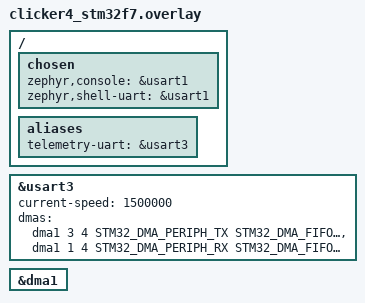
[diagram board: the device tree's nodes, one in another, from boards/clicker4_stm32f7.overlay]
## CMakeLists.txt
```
cmake_minimum_required(VERSION 3.20.0)

list(APPEND BOARD_ROOT ${CMAKE_CURRENT_SOURCE_DIR}/../..)

find_package(Zephyr REQUIRED HINTS $ENV{ZEPHYR_BASE})
project(zbus_uart_telemetry C)

target_include_directories(app PRIVATE include)

target_sources(app PRIVATE
  src/main.c
  src/channels.c
  src/host_command_dispatch.c
  src/sensor_stubs.c
  src/telemetry_encode.c
  src/uart_shared.c
  src/uart_publisher.c
  src/uart_subscriber.c
)

# Export HEX to a stable project-local path for external flash tools (e.g. CodeGrip).
set(CODEGRIP_OUTPUT_DIR "${CMAKE_CURRENT_SOURCE_DIR}/output")
set(CODEGRIP_INPUT_HEX "${PROJECT_BINARY_DIR}/zephyr/zephyr.hex")
set(CODEGRIP_OUTPUT_HEX "${CODEGRIP_OUTPUT_DIR}/zephyr-clicker4_stm32f7.hex")

add_custom_command(
  OUTPUT "${CODEGRIP_OUTPUT_HEX}"
  COMMAND ${CMAKE_COMMAND} -E make_directory "${CODEGRIP_OUTPUT_DIR}"
  COMMAND ${CMAKE_COMMAND} -E copy_if_different "${CODEGRIP_INPUT_HEX}" "${CODEGRIP_OUTPUT_HEX}"
  DEPENDS "${CODEGRIP_INPUT_HEX}"
  COMMENT "Exporting zephyr.hex for CodeGrip"
  VERBATIM
)

add_custom_target(export_codegrip_hex ALL
  DEPENDS "${CODEGRIP_OUTPUT_HEX}"
)
```

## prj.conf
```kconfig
CONFIG_SERIAL=y
CONFIG_ARM_MPU=y
CONFIG_NOCACHE_MEMORY=y
CONFIG_UART_ASYNC_API=y
CONFIG_UART_INTERRUPT_DRIVEN=y
CONFIG_UART_LINE_CTRL=y

CONFIG_ZBUS=y

CONFIG_THREAD_NAME=y
CONFIG_MAIN_STACK_SIZE=2048

CONFIG_LOG=y
CONFIG_LOG_MODE_DEFERRED=y
CONFIG_LOG_DEFAULT_LEVEL=3
CONFIG_LOG_BACKEND_UART=y
CONFIG_CONSOLE=y
CONFIG_UART_CONSOLE=y

CONFIG_ASSERT=y
```

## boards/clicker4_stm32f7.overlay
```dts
#include <zephyr/dt-bindings/dma/stm32_dma.h>

/ {
    chosen {
        zephyr,console = &usart1;
        zephyr,shell-uart = &usart1;
    };

    aliases {
        telemetry-uart = &usart3;
    };
};

&usart3 {
    current-speed = <1500000>;
    dmas = <&dma1 3 4 STM32_DMA_PERIPH_TX STM32_DMA_FIFO_1_4>,
           <&dma1 1 4 STM32_DMA_PERIPH_RX STM32_DMA_FIFO_1_4>;
    dma-names = "tx", "rx";
};

&dma1 {
    status = "okay";
};
```

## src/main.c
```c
#include <zephyr/kernel.h>
#include <zephyr/logging/log.h>

#include "app_threads.h"

LOG_MODULE_REGISTER(app_main, LOG_LEVEL_ERR);

int main(void)
{
    int ret = uart_shared_start();
    if (ret != 0) {
        LOG_ERR("UART shared transport failed to start (%d); stubs not started", ret);
        while (1) {
            k_sleep(K_SECONDS(1));
        }
    }

    ret = uart_publisher_start();
    if (ret != 0) {
        LOG_ERR("UART publisher failed to start (%d); stubs not started", ret);
        while (1) {
            k_sleep(K_SECONDS(1));
        }
    }

    ret = uart_subscriber_start();
    if (ret != 0) {
        LOG_ERR("UART subscriber failed to start (%d); stubs not started", ret);
        while (1) {
            k_sleep(K_SECONDS(1));
        }
    }

    lsm6dsox_stub_start();
    ads1115_stub_start();
    ina3221_stub_start();
    bq76942_stub_start();
    ina226_stub_start();
    heartbeat_stub_start();
    rc_command_stub_start();
    host_command_stub_start();

    while (1) {
        k_sleep(K_SECONDS(1));
    }

    return 0;
}
```

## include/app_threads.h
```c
#ifndef PROJECT_APP_THREADS_H_
#define PROJECT_APP_THREADS_H_

void lsm6dsox_stub_start(void);
void ads1115_stub_start(void);
void ina3221_stub_start(void);
void bq76942_stub_start(void);
void ina226_stub_start(void);
void heartbeat_stub_start(void);
void rc_command_stub_start(void);
void host_command_stub_start(void);
int uart_shared_start(void);
int uart_publisher_start(void);
int uart_subscriber_start(void);

#endif
```

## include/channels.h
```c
#ifndef PROJECT_CHANNELS_H_
#define PROJECT_CHANNELS_H_

/*
 * Compatibility umbrella header.
 * Prefer including telemetry_channels.h or host_channels.h directly.
 */

#include "host_channels.h"
#include "telemetry_channels.h"

#endif
```

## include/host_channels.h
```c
#ifndef PROJECT_HOST_CHANNELS_H_
#define PROJECT_HOST_CHANNELS_H_

#include <zephyr/zbus/zbus.h>

#include "messages.h"

/*
 * Host-to-MCU command channels (not forwarded over telemetry UART).
 * New host command message types should add a dedicated channel here.
 */
ZBUS_CHAN_DECLARE(servo_control_chan);
ZBUS_CHAN_DECLARE(host_heartbeat_chan);

#endif
```

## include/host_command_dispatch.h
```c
#ifndef PROJECT_HOST_COMMAND_DISPATCH_H_
#define PROJECT_HOST_COMMAND_DISPATCH_H_

#include <stdbool.h>

/*
 * Dispatch one host command line (without trailing newline).
 * Returns true if a known command was parsed and published.
 */
bool host_command_dispatch_line(const char *line);

#endif
```

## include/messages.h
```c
#ifndef PROJECT_MESSAGES_H_
#define PROJECT_MESSAGES_H_

#include <stdbool.h>
#include <stdint.h>

/*
 * Message schema definitions (payload only).
 *
 * Extension flow:
 * 1) Add/modify a struct here (keep `t_ms` + `seq` for telemetry messages).
 * 2) Bind topic->message in topic_registry.h.
 * 3) Add channel default in src/channels.c.
 * 4) Add encoder in telemetry_encode.c.
 * 5) Publish data from a producer thread/stub.
 */

struct heartbeat_msg {
    uint32_t t_ms;
    uint32_t seq;
};

struct rc_command_msg {
    uint32_t t_ms;
    uint32_t seq;
    int8_t steering;
    int8_t throttle;
    bool high_gear;
    bool diff_lock;
    bool override_mode;
    bool connected;
};

struct servo_control_msg {
    uint32_t t_ms;
    uint32_t seq;
    int8_t steering;
    int8_t throttle;
    bool high_gear;
    bool front_diff;
    bool rear_diff;
    int8_t extra1;
    int8_t extra2;
};

struct host_heartbeat_msg {
    uint32_t t_ms;
    uint32_t seq;
};

struct lsm6dsox_msg {
    uint32_t t_ms;
    uint32_t seq;
    float ax_mg;
    float ay_mg;
    float az_mg;
    float gx_mdps;
    float gy_mdps;
    float gz_mdps;
    float temp_cdeg;
};

struct ads1115_msg {
    uint32_t t_ms;
    uint32_t seq;
    float ain0_mv;
    float ain1_mv;
    float ain2_mv;
    float ain3_mv;
};

struct ina3221_msg {
    uint32_t t_ms;
    uint32_t seq;
    float ch1_bus_mv;
    float ch1_current_ma;
    float ch1_power_mw;
    float ch2_bus_mv;
    float ch2_current_ma;
    float ch2_power_mw;
    float ch3_bus_mv;
    float ch3_current_ma;
    float ch3_power_mw;
};

struct bq76942_msg {
    uint32_t t_ms;
    uint32_t seq;
    float pack_mv;
    float pack_ma;
    float soc_pct;
    float temp_cdeg;
    float cell_min_mv;
    float cell_avg_mv;
    float cell_max_mv;
    uint32_t error_flags;
};

struct ina226_msg {
    uint32_t t_ms;
    uint32_t seq;
    float bus_mv;
    float shunt_uv;
    float current_ma;
    float power_mw;
};

#endif
```

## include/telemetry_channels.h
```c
#ifndef PROJECT_TELEMETRY_CHANNELS_H_
#define PROJECT_TELEMETRY_CHANNELS_H_

#include <zephyr/zbus/zbus.h>

#include "messages.h"
#include "topic_registry.h"

/* Subscriber used by the telemetry UART publisher thread. */
ZBUS_OBS_DECLARE(uart_pub_sub);

/* Topic channels are declared from the central registry. */
#define CHANNEL_DECLARE_ENTRY(id, topic_name, chan_name, type_name, priority) \
    ZBUS_CHAN_DECLARE(chan_name);
TELEMETRY_TOPIC_LIST(CHANNEL_DECLARE_ENTRY)
#undef CHANNEL_DECLARE_ENTRY

#endif
```

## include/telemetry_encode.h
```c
#ifndef PROJECT_TELEMETRY_ENCODE_H_
#define PROJECT_TELEMETRY_ENCODE_H_

#include <stdbool.h>
#include <stddef.h>
#include <stdint.h>

#include "topic_registry.h"

/*
 * Encoders convert message structs into one framed payload body.
 * uart_publisher owns framing/transport; this module owns schema encoding.
 */

typedef bool (*telemetry_topic_encode_fn)(uint8_t *payload,
                                          size_t payload_cap,
                                          size_t *payload_len,
                                          const char *topic,
                                          const void *msg);

bool telemetry_encode_status_online(uint8_t *payload,
                                    size_t payload_cap,
                                    size_t *payload_len,
                                    uint32_t t_ms);

/* Encoder declarations stay aligned with TELEMETRY_TOPIC_LIST entries. */
#define TELEMETRY_ENCODER_DECLARE(id, topic_name, chan_name, type_name, priority) \
    bool telemetry_encode_##type_name(uint8_t *payload,                            \
                                      size_t payload_cap,                           \
                                      size_t *payload_len,                          \
                                      const char *topic,                            \
                                      const void *msg);
TELEMETRY_TOPIC_LIST(TELEMETRY_ENCODER_DECLARE)
#undef TELEMETRY_ENCODER_DECLARE

#endif
```

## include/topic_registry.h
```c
#ifndef PROJECT_TOPIC_REGISTRY_H_
#define PROJECT_TOPIC_REGISTRY_H_

/*
 * Central telemetry topic registry.
 * Add new entries here so channel declarations, topic enums, and publisher
 * routing stay aligned.
 *
 * Each entry is:
 *   X(ID, topic_label, channel_symbol, message_type, priority)
 * Priority rule: larger value wins when multiple topics are pending.
 */

#define TELEMETRY_TOPIC_LIST(X)                                    \
    X(HEARTBEAT, heartbeat, heartbeat_chan, heartbeat_msg, 10)     \
    X(RC_COMMAND, rc_command, rc_command_chan, rc_command_msg, 95) \
    X(LSM6DSOX, lsm6dsox, lsm6dsox_chan, lsm6dsox_msg, 40)         \
    X(ADS1115, ads1115, ads1115_chan, ads1115_msg, 50)             \
    X(INA3221_A, ina3221_a, ina3221_a_chan, ina3221_msg, 60)       \
    X(INA3221_B, ina3221_b, ina3221_b_chan, ina3221_msg, 60)       \
    X(BQ76942, bq76942, bq76942_chan, bq76942_msg, 100)            \
    X(INA226_A, ina226_a, ina226_a_chan, ina226_msg, 70)           \
    X(INA226_B, ina226_b, ina226_b_chan, ina226_msg, 70)

enum sensor_topic_id {
#define TOPIC_ENUM_ENTRY(id, topic_name, chan_name, type_name, priority) TOPIC_##id,
    TELEMETRY_TOPIC_LIST(TOPIC_ENUM_ENTRY)
#undef TOPIC_ENUM_ENTRY
        TOPIC_COUNT
};

#endif
```

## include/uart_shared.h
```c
#ifndef PROJECT_UART_SHARED_H_
#define PROJECT_UART_SHARED_H_

#include <zephyr/device.h>
#include <zephyr/drivers/uart.h>

/*
 * Shared UART transport ownership:
 * - one callback is installed on the telemetry UART
 * - publisher/subscriber modules register their event handlers here
 */

typedef void (*uart_shared_event_handler_t)(const struct device *dev,
                                            struct uart_event *evt,
                                            void *user_data);

int uart_shared_start(void);
const struct device *uart_shared_device(void);
int uart_shared_register_handler(uart_shared_event_handler_t handler, void *user_data);

#endif
```

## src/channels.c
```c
#include <zephyr/zbus/zbus.h>

#include "host_channels.h"
#include "telemetry_channels.h"

/* RX command channels are independent from outbound telemetry channels. */
ZBUS_SUBSCRIBER_DEFINE(uart_pub_sub, 256);

ZBUS_CHAN_DEFINE(servo_control_chan,
                 struct servo_control_msg,
                 NULL,
                 NULL,
                 ZBUS_OBSERVERS_EMPTY,
                 ZBUS_MSG_INIT(.t_ms = 0,
                               .seq = 0,
                               .steering = 0,
                               .throttle = 0,
                               .high_gear = false,
                               .front_diff = false,
                               .rear_diff = false,
                               .extra1 = 0,
                               .extra2 = 0));

ZBUS_CHAN_DEFINE(host_heartbeat_chan,
                 struct host_heartbeat_msg,
                 NULL,
                 NULL,
                 ZBUS_OBSERVERS_EMPTY,
                 ZBUS_MSG_INIT(.t_ms = 0,
                               .seq = 0));

ZBUS_CHAN_DEFINE(heartbeat_chan,
                 struct heartbeat_msg,
                 NULL,
                 NULL,
                 ZBUS_OBSERVERS(uart_pub_sub),
                 ZBUS_MSG_INIT(.t_ms = 0,
                               .seq = 0));

ZBUS_CHAN_DEFINE(rc_command_chan,
                 struct rc_command_msg,
                 NULL,
                 NULL,
                 ZBUS_OBSERVERS(uart_pub_sub),
                 ZBUS_MSG_INIT(.t_ms = 0,
                               .seq = 0,
                               .steering = 0,
                               .throttle = 0,
                               .high_gear = 0,
                               .diff_lock = 0,
                               .override_mode = 0,
                               .connected = 0));

ZBUS_CHAN_DEFINE(lsm6dsox_chan,
                 struct lsm6dsox_msg,
                 NULL,
                 NULL,
                 ZBUS_OBSERVERS(uart_pub_sub),
                 ZBUS_MSG_INIT(.t_ms = 0,
                               .seq = 0,
                               .ax_mg = 0,
                               .ay_mg = 0,
                               .az_mg = 0,
                               .gx_mdps = 0,
                               .gy_mdps = 0,
                               .gz_mdps = 0,
                               .temp_cdeg = 0));

ZBUS_CHAN_DEFINE(ads1115_chan,
                 struct ads1115_msg,
                 NULL,
                 NULL,
                 ZBUS_OBSERVERS(uart_pub_sub),
                 ZBUS_MSG_INIT(.t_ms = 0,
                               .seq = 0,
                               .ain0_mv = 0,
                               .ain1_mv = 0,
                               .ain2_mv = 0,
                               .ain3_mv = 0));

ZBUS_CHAN_DEFINE(ina3221_a_chan,
                 struct ina3221_msg,
                 NULL,
                 NULL,
                 ZBUS_OBSERVERS(uart_pub_sub),
                 ZBUS_MSG_INIT(.t_ms = 0,
                               .seq = 0,
                               .ch1_bus_mv = 0,
                               .ch1_current_ma = 0,
                               .ch1_power_mw = 0,
                               .ch2_bus_mv = 0,
                               .ch2_current_ma = 0,
                               .ch2_power_mw = 0,
                               .ch3_bus_mv = 0,
                               .ch3_current_ma = 0,
                               .ch3_power_mw = 0));

ZBUS_CHAN_DEFINE(ina3221_b_chan,
                 struct ina3221_msg,
                 NULL,
                 NULL,
                 ZBUS_OBSERVERS(uart_pub_sub),
                 ZBUS_MSG_INIT(.t_ms = 0,
                               .seq = 0,
                               .ch1_bus_mv = 0,
                               .ch1_current_ma = 0,
                               .ch1_power_mw = 0,
                               .ch2_bus_mv = 0,
                               .ch2_current_ma = 0,
                               .ch2_power_mw = 0,
                               .ch3_bus_mv = 0,
                               .ch3_current_ma = 0,
                               .ch3_power_mw = 0));

ZBUS_CHAN_DEFINE(bq76942_chan,
                 struct bq76942_msg,
                 NULL,
                 NULL,
                 ZBUS_OBSERVERS(uart_pub_sub),
                 ZBUS_MSG_INIT(.t_ms = 0,
                               .seq = 0,
                               .pack_mv = 0,
                               .pack_ma = 0,
                               .soc_pct = 0,
                               .temp_cdeg = 0,
                               .cell_min_mv = 0,
                               .cell_avg_mv = 0,
                               .cell_max_mv = 0,
                               .error_flags = 0));

ZBUS_CHAN_DEFINE(ina226_a_chan,
                 struct ina226_msg,
                 NULL,
                 NULL,
                 ZBUS_OBSERVERS(uart_pub_sub),
                 ZBUS_MSG_INIT(.t_ms = 0,
                               .seq = 0,
                               .bus_mv = 0,
                               .shunt_uv = 0,
                               .current_ma = 0,
                               .power_mw = 0));

ZBUS_CHAN_DEFINE(ina226_b_chan,
                 struct ina226_msg,
                 NULL,
                 NULL,
                 ZBUS_OBSERVERS(uart_pub_sub),
                 ZBUS_MSG_INIT(.t_ms = 0,
                               .seq = 0,
                               .bus_mv = 0,
                               .shunt_uv = 0,
                               .current_ma = 0,
                               .power_mw = 0));
```

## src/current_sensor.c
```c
#include <zephyr/kernel.h>
#include <zephyr/logging/log.h>

#include "channels.h"

LOG_MODULE_REGISTER(current_sensor, LOG_LEVEL_INF);

#define CURRENT_PERIOD_MS 50
#define CURRENT_STACK_SIZE 1024
#define CURRENT_THREAD_PRIO 4

static K_THREAD_STACK_DEFINE(current_stack, CURRENT_STACK_SIZE);
static struct k_thread current_thread;

static void current_thread_fn(void *a, void *b, void *c)
{
    ARG_UNUSED(a);
    ARG_UNUSED(b);
    ARG_UNUSED(c);

    uint32_t seq = 0;

    while (1) {
        struct current_msg msg;
        int32_t ripple = (int32_t)(seq % 80U) - 40;

        msg.t_ms = (uint32_t)k_uptime_get();
        msg.seq = seq;

        msg.bus_mv = 24000 + ripple * 5;
        msg.current_ma = 1500 + ripple * 12;
        msg.power_mw = (msg.bus_mv * msg.current_ma) / 1000;

        int err = zbus_chan_pub(&current_chan, &msg, K_MSEC(5));
        if (err != 0) {
            LOG_WRN("current publish failed: %d", err);
        }

        seq++;
        k_sleep(K_MSEC(CURRENT_PERIOD_MS));
    }
}

void current_sensor_start(void)
{
    k_thread_create(&current_thread,
                    current_stack,
                    K_THREAD_STACK_SIZEOF(current_stack),
                    current_thread_fn,
                    NULL,
                    NULL,
                    NULL,
                    CURRENT_THREAD_PRIO,
                    0,
                    K_NO_WAIT);

    k_thread_name_set(&current_thread, "current_sensor");
    LOG_INF("Current stub sensor started");
}
```

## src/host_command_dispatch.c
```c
#include <stdbool.h>
#include <stdint.h>
#include <stdio.h>

#include <zephyr/kernel.h>
#include <zephyr/sys/util.h>

#include "host_channels.h"

static int8_t clamp_i8(int v) {
    if (v > 127) {
        return 127;
    }
    if (v < -128) {
        return -128;
    }
    return (int8_t)v;
}

static bool dispatch_servo(const char *line) {
    unsigned long seq_ul = 0;
    int steering = 0;
    int throttle = 0;
    int high_gear = 0;
    int front_diff = 0;
    int rear_diff = 0;
    int extra1 = 0;
    int extra2 = 0;

    if (sscanf(line, "SERVO %lu %d %d %d %d %d %d %d",
               &seq_ul,
               &steering,
               &throttle,
               &high_gear,
               &front_diff,
               &rear_diff,
               &extra1,
               &extra2) != 8) {
        return false;
    }

    struct servo_control_msg msg = {
        .t_ms = (uint32_t)k_uptime_get(),
        .seq = (uint32_t)seq_ul,
        .steering = clamp_i8(steering),
        .throttle = clamp_i8(throttle),
        .high_gear = high_gear != 0,
        .front_diff = front_diff != 0,
        .rear_diff = rear_diff != 0,
        .extra1 = clamp_i8(extra1),
        .extra2 = clamp_i8(extra2),
    };
    (void)zbus_chan_pub(&servo_control_chan, &msg, K_NO_WAIT);
    return true;
}

static bool dispatch_hb(const char *line) {
    unsigned long seq_ul = 0;

    if (sscanf(line, "HB %lu", &seq_ul) != 1) {
        return false;
    }

    struct host_heartbeat_msg msg = {
        .t_ms = (uint32_t)k_uptime_get(),
        .seq = (uint32_t)seq_ul,
    };
    (void)zbus_chan_pub(&host_heartbeat_chan, &msg, K_NO_WAIT);
    return true;
}

struct host_cmd_dispatch_entry {
    bool (*dispatch)(const char *line);
};

/*
 * To add a new command:
 * 1) Add a dispatch_<name>() function.
 * 2) Append it to this table.
 */
static const struct host_cmd_dispatch_entry dispatch_table[] = {
    {.dispatch = dispatch_servo},
    {.dispatch = dispatch_hb},
};

bool host_command_dispatch_line(const char *line) {
    for (size_t i = 0; i < ARRAY_SIZE(dispatch_table); i++) {
        if (dispatch_table[i].dispatch(line)) {
            return true;
        }
    }
    return false;
}
```
